# MINI51AN_v1 register map
File version: 1.0
Registers are 32-bit, read-write, reset 0x0 unless marked. A register's access mark holds for its fields unless they carry their own. Offsets are from the block's base; [hi:lo] are bit positions; 'fields as' and 'values as' point back to an identical list.

## TMR — TMR Register Map
Base 0x40010000
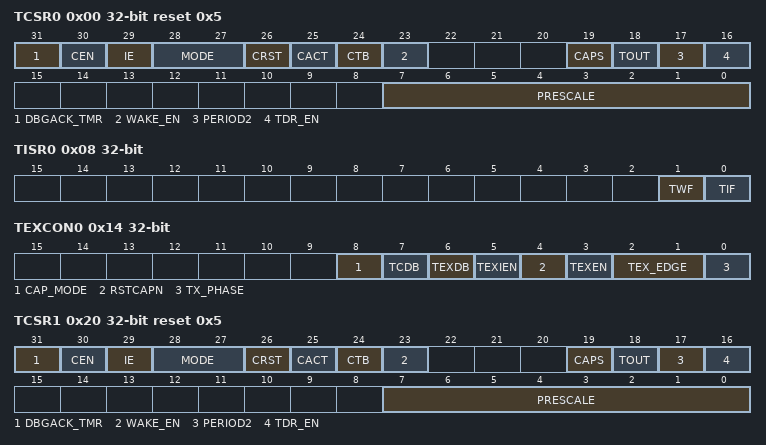
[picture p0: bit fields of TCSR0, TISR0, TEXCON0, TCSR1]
0x00 TCSR0 reset 0x5 — Timer0 Control and Status Register
  [31] DBGACK_TMR — ICE Debug Mode Acknowledge Disable (Write-protection Bit). The TIMER counter will be held while ICE Debug mode acknowledged.
    0=ICE Debug mode acknowledgement effects TIMER counting; 1=ICE Debug mode acknowledgement Disabled
  [30] CEN — Timer Enable Bit
    0=Counting stopped/suspended; 1=Counting started
  [29] IE — Interrupt Enable Bit. If timer interrupt is enabled, the timer asserts its interrupt signal when the associated up-timer value is equal to TCMPR.
    0=Timer Interrupt Disabled; 1=Timer Interrupt Enabled
  [28:27] MODE — Timer Operating Mode
  [26] CRST — Timer Reset Bit. Set this bit will reset the 24-bit up-timer, 8-bit pre-scale counter and also force CEN to 0.
    0=No effect; 1=Timer's 8-bit pre-scale counter, internal 24-bit up-timer and CEN bit reset
  [25] CACT ro — Timer Active Status Bit (Read only). This bit indicates the up-timer status.
    0=Timer not active; 1=Timer active
  [24] CTB — Counter Mode Enable Bit. This bit is the counter mode enable bit. When Timer is used as an event counter, this bit should be set to 1 and Timer will work as an event counter. The counter detect phase can be selected as rising/falling edge of external pin by TX_PHASE field.
    0=Counter mode Disabled; 1=Counter mode Enabled
  [23] WAKE_EN — Wake-Up Enable. When WAKE_EN is set and the TIF or TEXIF is set, the timer controller will generator a wake-up trigger event to CPU.
    0=Wake-up trigger event Disabled; 1=Wake-up trigger event Enabled
  [19] CAPS — Capture Trigger Source Selection
    0=Time0/1 capture mode trigger input source is T0EX/T1EX pin; 1=Time0/1 capture mode trigger input source is ACMP0/ACMP1 output
  [18] TOUT — Toggle Out Pin Selection. When Timer is set to toggle mode,
    0=Time0/1 toggle output pin is T0/T1 pin; 1=Time0/1 toggle output pin is T0EX/T1EX pin
  [17] PERIOD2 — PERIOD2 Enable Bit
    0=In One-shout or Periodic mode, when write new TCMP, timer counter will reset; 1=In One-shout or Periodic mode, when write new TCMP
  [16] TDR_EN — Data Load Enable. When TDR_EN is set, TDR (Timer Data Register) will be updated continuously with the 24-bit up-timer value as the timer is counting.
    0=Timer Data Register update Disabled; 1=Timer Data Register update Enabled
  [7:0] PRESCALE — Pre-Scale Counter
0x04 TCMPR0 — Timer0 Compare Register
  [23:0] TCMP — Timer Compared Value. Note1: Never write 0 or 1 in TCMP, or the core will run into unknown state. Note2: When timer is operating at continuous counting mode, the 24-bit up-timer will count continuously if software writes a new value into TCMP. If timer is operating at other modes, the 24-bit up-timer will restart counting and using newest TCMP value to be the compared value if software writes a new value into TCMP.
0x08 TISR0 — Timer0 Interrupt Status Register
  [1] TWF — Timer Wake-up Flag. If timer causes CPU wakes up from power-down mode, this bit will be set to high. Software can write 1 to clear this bit.
    0=Timer does not cause CPU wake-up; 1=CPU wakes up from sleep or power-down mode by timer time-out
  [0] TIF — Timer Interrupt Flag. This bit indicates the interrupt status of timer.
0x0C TDR0 ro — Timer0 Data Register
  [23:0] TDR — Timer Data Register. This field indicates the current count value.
0x10 TCAP0 ro — Timer0 Capture Data Register
  [23:0] TCAP — Timer Capture Data Register. When TEXEN (TEXCON[3]) is set, RSTCAPN (TEXCON[4]) is 0, and the transition on the TEX pins associated TEX_EDGE (TEXCON[2:1]) setting is occurred, the internal 24-bit up-timer value will be loaded into TCAP. User can read this register for the counter value.
0x14 TEXCON0 — Timer0 External Control Register
  [8] CAP_MODE — Capture Mode Selection
    0=Timer counter reset function or free-counting mode of timer capture function; 1=Trigger-counting mode of timer capture function
  [7] TCDB — Timer Counter Pin De-bounce Enable Bit. If this bit is enabled, the edge of T0~T1 pin is detected with de-bounce circuit.
    0=De-bounce Disabled; 1=De-bounce Enabled
  [6] TEXDB — Timer External Capture Pin De-bounce Enable Bit. If this bit is enabled, the edge of TEX pin is detected with de-bounce circuit.
    0=De-bounce Disabled; 1=De-bounce Enabled
  [5] TEXIEN — Timer External Interrupt Enable Bit
    0=Timer External Interrupt Disabled; 1=Timer External Interrupt Enabled
  [4] RSTCAPN — Timer External Reset Counter / Capture Mode Selection
    0=TEX transition is used as the timer capture function; 1=TEX transition is used as the timer counter reset function
  [3] TEXEN — Timer External Pin Enable. This bit enables the reset/capture function on the TEX pin.
    0=The TEX pin will be ignored; 1=The transition detected on the TEX pin will result in capture or reset of timer counter
  [2:1] TEX_EDGE — Timer External Pin Edge Detection
  [0] TX_PHASE — Timer External Count Phase. This bit indicates the external count pin phase.
    0=A falling edge of external count pin will be counted; 1=A rising edge of external count pin will be counted
0x18 TEXISR0 — Timer0 External Interrupt Status Register
  [0] TEXIF — Timer External Interrupt Flag. This bit indicates the external interrupt status of the timer. This bit is set by hardware when TEXEN (TEXCON[3]) is to 1, and the transition on the TEX pins associated with TEX_EDGE (TEXCON[2:1]) setting occurred. Software can write 1 to clear this bit.
0x20 TCSR1 reset 0x5 — Timer1 Control and Status Register
  fields as TCSR0
0x24 TCMPR1 — Timer1 Compare Register
  fields as TCMPR0
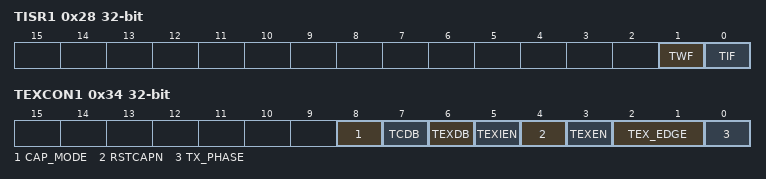
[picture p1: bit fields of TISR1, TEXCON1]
0x28 TISR1 — Timer1 Interrupt Status Register
  fields as TISR0
0x2C TDR1 ro — Timer1 Data Register
  fields as TDR0
0x30 TCAP1 ro — Timer1 Capture Data Register
  fields as TCAP0
0x34 TEXCON1 — Timer1 External Control Register
  fields as TEXCON0
0x38 TEXISR1 — Timer1 External Interrupt Status Register
  fields as TEXISR0
